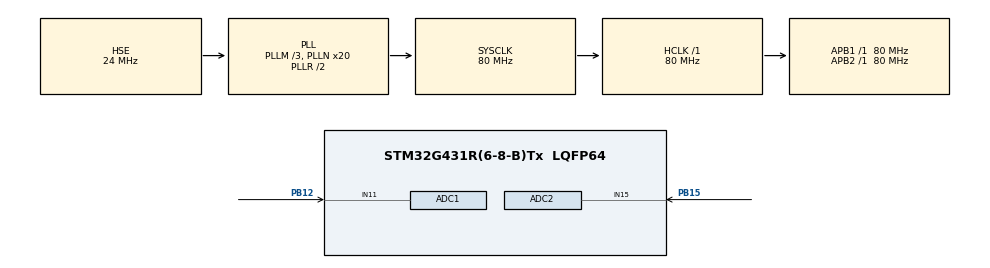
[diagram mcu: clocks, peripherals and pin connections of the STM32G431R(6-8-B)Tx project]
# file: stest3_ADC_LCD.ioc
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ADC1.Channel-0\#ChannelRegularConversion=ADC_CHANNEL_11
ADC1.ContinuousConvMode=ENABLE
ADC1.DMAContinuousRequests=ENABLE
ADC1.NbrOfConversionFlag=1
ADC1.OffsetNumber-0\#ChannelRegularConversion=ADC_OFFSET_NONE
ADC1.Rank-0\#ChannelRegularConversion=1
ADC1.SamplingTime-0\#ChannelRegularConversion=ADC_SAMPLETIME_2CYCLES_5
ADC1.master=1
ADC2.Channel-0\#ChannelRegularConversion=ADC_CHANNEL_15
ADC2.ContinuousConvMode=ENABLE
ADC2.DMAContinuousRequests=ENABLE
ADC2.NbrOfConversionFlag=1
ADC2.OffsetNumber-0\#ChannelRegularConversion=ADC_OFFSET_NONE
ADC2.Rank-0\#ChannelRegularConversion=1
ADC2.SamplingTime-0\#ChannelRegularConversion=ADC_SAMPLETIME_2CYCLES_5
Dma.ADC1.0.Direction=DMA_PERIPH_TO_MEMORY
Dma.ADC1.0.EventEnable=DISABLE
Dma.ADC1.0.Instance=DMA1_Channel1
Dma.ADC1.0.MemDataAlignment=DMA_MDATAALIGN_HALFWORD
Dma.ADC1.0.MemInc=DMA_MINC_ENABLE
Dma.ADC1.0.Mode=DMA_CIRCULAR
Dma.ADC1.0.PeriphDataAlignment=DMA_PDATAALIGN_HALFWORD
Dma.ADC1.0.PeriphInc=DMA_PINC_DISABLE
Dma.ADC1.0.Polarity=HAL_DMAMUX_REQ_GEN_RISING
Dma.ADC1.0.Priority=DMA_PRIORITY_LOW
Dma.ADC1.0.RequestNumber=1
Dma.ADC1.0.SignalID=NONE
Dma.ADC1.0.SyncEnable=DISABLE
Dma.ADC1.0.SyncPolarity=HAL_DMAMUX_SYNC_NO_EVENT
Dma.ADC1.0.SyncRequestNumber=1
Dma.ADC1.0.SyncSignalID=NONE
Dma.ADC2.1.Direction=DMA_PERIPH_TO_MEMORY
Dma.ADC2.1.EventEnable=DISABLE
Dma.ADC2.1.Instance=DMA1_Channel2
Dma.ADC2.1.MemDataAlignment=DMA_MDATAALIGN_HALFWORD
Dma.ADC2.1.MemInc=DMA_MINC_ENABLE
Dma.ADC2.1.Mode=DMA_CIRCULAR
Dma.ADC2.1.PeriphDataAlignment=DMA_PDATAALIGN_HALFWORD
Dma.ADC2.1.PeriphInc=DMA_PINC_DISABLE
Dma.ADC2.1.Polarity=HAL_DMAMUX_REQ_GEN_RISING
Dma.ADC2.1.Priority=DMA_PRIORITY_LOW
Dma.ADC2.1.RequestNumber=1
Dma.ADC2.1.SignalID=NONE
Dma.ADC2.1.SyncEnable=DISABLE
Dma.ADC2.1.SyncPolarity=HAL_DMAMUX_SYNC_NO_EVENT
Dma.ADC2.1.SyncRequestNumber=1
Dma.ADC2.1.SyncSignalID=NONE
Dma.Request0=ADC1
Dma.Request1=ADC2
Mcu.Family=STM32G4
Mcu.Name=STM32G431R(6-8-B)Tx
Mcu.Package=LQFP64
NVIC.PriorityGroup=NVIC_PRIORITYGROUP_4
PA13.Mode=Serial_Wire
PA13.Signal=SYS_JTMS-SWDIO
PA14.Mode=Serial_Wire
PA14.Signal=SYS_JTCK-SWCLK
PB12.Mode=IN11-Single-Ended
PB12.Signal=ADC1_IN11
PB15.Mode=IN15-Single-Ended
PB15.Signal=ADC2_IN15
PF0-OSC_IN.Mode=HSE-External-Oscillator
PF0-OSC_IN.Signal=RCC_OSC_IN
PF1-OSC_OUT.Mode=HSE-External-Oscillator
PF1-OSC_OUT.Signal=RCC_OSC_OUT
ProjectManager.HeapSize=0x200
ProjectManager.StackSize=0x400
ProjectManager.TargetToolchain=MDK-ARM V5.32
RCC.ADC12Freq_Value=80000000
RCC.AHBFreq_Value=80000000
RCC.APB1Freq_Value=80000000
RCC.APB1TimFreq_Value=80000000
RCC.APB2Freq_Value=80000000
RCC.APB2TimFreq_Value=80000000
RCC.CortexFreq_Value=80000000
RCC.EXTERNAL_CLOCK_VALUE=12288000
RCC.HCLKFreq_Value=80000000
RCC.HSE_VALUE=24000000
RCC.HSI48_VALUE=48000000
RCC.HSI_VALUE=16000000
RCC.LSE_VALUE=32768
RCC.PLLM=RCC_PLLM_DIV3
RCC.PLLN=20
RCC.PLLSourceVirtual=RCC_PLLSOURCE_HSE
RCC.SYSCLKFreq_VALUE=80000000
RCC.SYSCLKSource=RCC_SYSCLKSOURCE_PLLCLK
RCC.USBFreq_Value=80000000
RCC.VCOOutputFreq_Value=160000000
VP_SYS_VS_DBSignals.Mode=DisableDeadBatterySignals
board=custom

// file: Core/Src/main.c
/* USER CODE BEGIN Header */
/**
  ******************************************************************************
  * @file           : main.c
  * @brief          : Main program body
  ******************************************************************************
  * @attention
  *
  * Copyright (c) 2025 STMicroelectronics.
  * All rights reserved.
  *
  * This software is licensed under terms that can be found in the LICENSE file
  * in the root directory of this software component.
  * If no LICENSE file comes with this software, it is provided AS-IS.
  *
  ******************************************************************************
  */
/* USER CODE END Header */
#include "main.h"
#include "adc.h"
#include "dma.h"
#include "gpio.h"

/* USER CODE BEGIN Includes */
#include "lcd.h"
#include "user.h"
/* USER CODE END Includes */

/* USER CODE BEGIN PV */
extern uint16_t adc2value[30];
/* USER CODE END PV */

void SystemClock_Config(void);

int main(void)
{

  /* MCU Configuration--------------------------------------------------------*/

  /* Reset of all peripherals, Initializes the Flash interface and the Systick. */
  HAL_Init();

  /* Configure the system clock */
  SystemClock_Config();

  /* Initialize all configured peripherals */
  MX_GPIO_Init();
  MX_DMA_Init();
  MX_ADC1_Init();
  MX_ADC2_Init();
  /* USER CODE BEGIN 2 */
	GPIOC->ODR=0xffff;
	GPIOD->ODR|=0x0004;
	GPIOD->ODR&=0xfffb;

	LCD_Init();
HAL_ADC_Start_DMA(&hadc2,(uint32_t *)adc2value,1);
HAL_ADCEx_Calibration_Start(&hadc2,ADC_SINGLE_ENDED);
LCD_Clear(Black);
LCD_SetBackColor(Black);
LCD_SetTextColor(White);

  /* USER CODE END 2 */

  /* Infinite loop */
  /* USER CODE BEGIN WHILE */
  while (1)
  {
		adc_lcd();
    /* USER CODE END WHILE */

  }
}

void SystemClock_Config(void)
{
  RCC_OscInitTypeDef RCC_OscInitStruct = {0};
  RCC_ClkInitTypeDef RCC_ClkInitStruct = {0};

  /** Configure the main internal regulator output voltage
  */
  HAL_PWREx_ControlVoltageScaling(PWR_REGULATOR_VOLTAGE_SCALE1);

  /** Initializes the RCC Oscillators according to the specified parameters
  * in the RCC_OscInitTypeDef structure.
  */
  RCC_OscInitStruct.OscillatorType = RCC_OSCILLATORTYPE_HSE;
  RCC_OscInitStruct.HSEState = RCC_HSE_ON;
  RCC_OscInitStruct.PLL.PLLState = RCC_PLL_ON;
  RCC_OscInitStruct.PLL.PLLSource = RCC_PLLSOURCE_HSE;
  RCC_OscInitStruct.PLL.PLLM = RCC_PLLM_DIV3;
  RCC_OscInitStruct.PLL.PLLN = 20;
  RCC_OscInitStruct.PLL.PLLP = RCC_PLLP_DIV2;
  RCC_OscInitStruct.PLL.PLLQ = RCC_PLLQ_DIV2;
  RCC_OscInitStruct.PLL.PLLR = RCC_PLLR_DIV2;
  if (HAL_RCC_OscConfig(&RCC_OscInitStruct) != HAL_OK)
  {
    Error_Handler();
  }

  /** Initializes the CPU, AHB and APB buses clocks
  */
  RCC_ClkInitStruct.ClockType = RCC_CLOCKTYPE_HCLK|RCC_CLOCKTYPE_SYSCLK
                              |RCC_CLOCKTYPE_PCLK1|RCC_CLOCKTYPE_PCLK2;
  RCC_ClkInitStruct.SYSCLKSource = RCC_SYSCLKSOURCE_PLLCLK;
  RCC_ClkInitStruct.AHBCLKDivider = RCC_SYSCLK_DIV1;
  RCC_ClkInitStruct.APB1CLKDivider = RCC_HCLK_DIV1;
  RCC_ClkInitStruct.APB2CLKDivider = RCC_HCLK_DIV1;

  if (HAL_RCC_ClockConfig(&RCC_ClkInitStruct, FLASH_LATENCY_2) != HAL_OK)
  {
    Error_Handler();
  }
}

void Error_Handler(void)
{
  __disable_irq();
  while (1)
  {
  }
}
